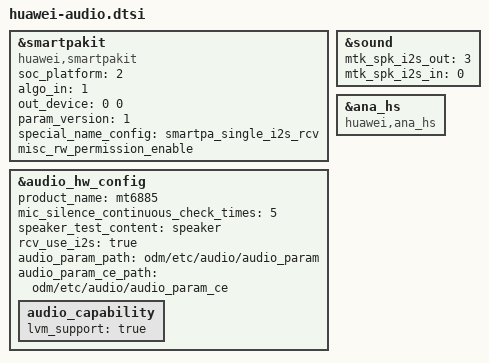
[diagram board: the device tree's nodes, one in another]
#include "../huawei_audio/huawei_mt6359_accdet.dtsi"
#include "../huawei_audio/huawei_mt6885_audio_dsp.dtsi"
#include "../huawei_audio/oce/smartpa_v3.dtsi"
#include "../huawei_audio/oce/huawei_audio_oce.dtsi"

&smartpakit {
	compatible = "huawei,smartpakit";
	/* 0 hisi, 1 qcom, 2 mtk */
	soc_platform = <2>;
	/* algo running on: 0 codec_dsp, 1 soc_dsp, 2 smartpa_dsp, 3 simple pa(not smpartpa), 4 simple pa(with i2c) */
	algo_in = <1>;
	/* algo_in params need match out_device for smartpa.
	 * Now, up to only support four pa, so out_device = <0 0 0 0>;
	 * 1. This array is arranged in the following order:
	 *    <0 1 2 3>
	 *    <pril prir secl secr>
	 * 2. This array element value is 0 or 1:
	 *    smartpa: 0 speaker, 1 receiver
	 *    simple pa: out_device not applicable, only set 0 to indicate pa_num
	 * 3. The length of this array is variable, for example:
	 *    single pa: out_device = <0>;
	 *    two pa: out_device = <0 0>;
	 *    four pa: out_device = <1 1 0 0>; */
	out_device = <0 0>;
	/* param_version: 1 mixed smartpa param support */
	param_version = <1>;
	special_name_config = "smartpa_single_i2s_rcv";
	misc_rw_permission_enable;
	status = "ok";
};

&audio_hw_config {
	product_name = "mt6885";
	mic_silence_continuous_check_times = "5";
	speaker_test_content = "speaker";
	rcv_use_i2s = "true";
	audio_param_path = "odm/etc/audio/audio_param";
	audio_param_ce_path = "odm/etc/audio/audio_param_ce";
	audio_capability {
		lvm_support = "true";
	};
};

&sound{
	mtk_spk_i2s_out = <3>;
	mtk_spk_i2s_in = <0>;
};

&ana_hs {
	compatible = "huawei,ana_hs";
	status = "ok";
};
